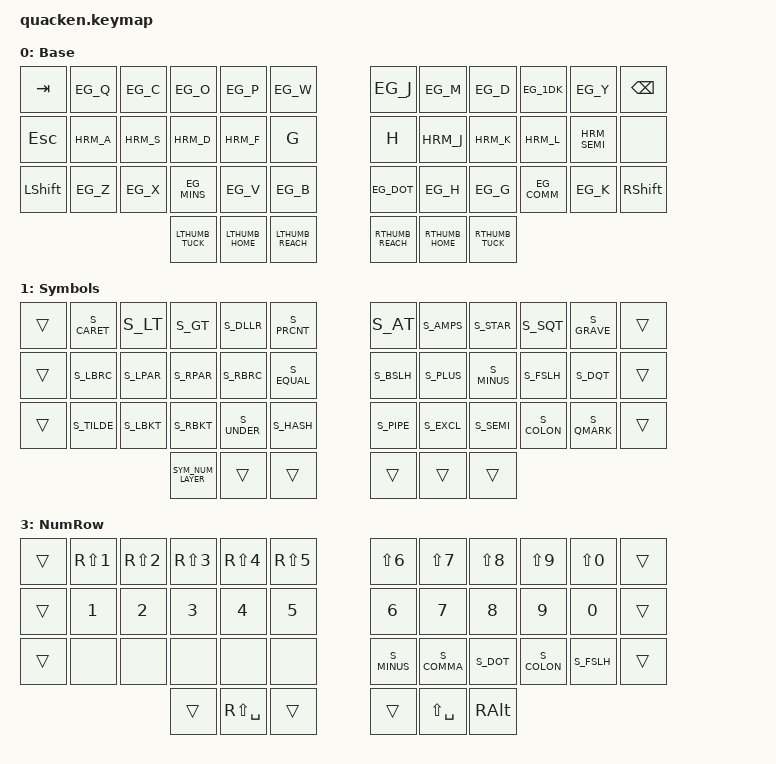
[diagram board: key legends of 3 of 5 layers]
// Selenium keymap:
// https://github.com/OneDeadKey/selenium

#ifndef CI_IGNORE_USER_SETTINGS
  #include "settings.h"   // user settings, ignored by CI tests
#endif

#include "aliases.h"      // symbols, actions, non-ASCII chars
#include "mappings.dtsi"  // key mapping helpers and macros
#include "my_hold_taps.dtsi" // thumb keys and homerow mods

/ {
  keymap {
    compatible = "zmk,keymap";

    // 0. Base layer -- keep the QWERTY key codes to use your OS keyboard layout
    //               -- the Space Cadet layer-tap on the right can be replaced by an AltGr/Enter mod-tap
    //               -- adjust the homerow mods with the #define statements above
    base_layer: base_layer {
      display-name = "Base";
      bindings = <
        &kp TAB    EG_Q    EG_C   EG_O    EG_P   EG_W         EG_J    EG_M    EG_D     EG_1DK   EG_Y       &kp BACKSPACE
        &kp ESCAPE HRM_A   HRM_S  HRM_D   HRM_F  &kp G        &kp H   HRM_J   HRM_K    HRM_L    HRM_SEMI   &none
        &kp LSHIFT EG_Z    EG_X   EG_MINS EG_V   EG_B         EG_DOT  EG_H    EG_G     EG_COMM  EG_K       &kp RSHIFT
                LTHUMB_TUCK  LTHUMB_HOME  LTHUMB_REACH    RTHUMB_REACH  RTHUMB_HOME  RTHUMB_TUCK
      >;
    };

    // 1. Symbols layer -- with Ergo-L, basically just an AltGr layer with custom thumb keys
    //                  -- can be redefined for non-AltGr layouts such as QWERTY-ANSI
    symbols_layer: symbols_layer {
      display-name = "Symbols";
      bindings = <
        &trans  S_CARET S_LT    S_GT    S_DLLR  S_PRCNT       S_AT    S_AMPS  S_STAR  S_SQT   S_GRAVE  &trans
        &trans  S_LBRC  S_LPAR  S_RPAR  S_RBRC  S_EQUAL       S_BSLH  S_PLUS  S_MINUS S_FSLH  S_DQT    &trans
        &trans  S_TILDE S_LBKT  S_RBKT  S_UNDER S_HASH        S_PIPE  S_EXCL  S_SEMI  S_COLON S_QMARK  &trans
                         SYM_NUM_LAYER  &trans  &trans        &trans  &trans  &trans
      >;
    };

    // 2. VimNav layer -- HJKL arrow cluster on the right hand
    //                 -- best used along with the NumRow layer
    //                 -- keyboard shortcuts on the left hand are adjusted to the OS layout (Ergo-L here)
    vim_nav_layer: vim_nav_layer {
      display-name = "VimNav";
      bindings = <
        &trans  &none    X_CTL_W  &vim_prev &vim_next &none        &none    &kp HOME  &kp PG_DN &kp PG_UP &kp END   &trans
        &trans  X_ALL    X_SAVE  X_SHTAB   H_F TAB   &none         &none    &kp LEFT  &kp DOWN  &kp UP    &kp RIGHT &trans
        &trans  X_UNDO   X_CUT    X_COPY    X_PASTE   X_REDO       &none    CLOSE_T   PREV_T    NEXT_T    OPEN_T    &trans
          &kp CAPS  &lt FN_MEDIA_LAYER DEL  &mo NUM_ROW_LAYER    &trans  &mo FN_MEDIA_LAYER  &EZ_LSK(RALT)
      >;
    };

    // 3. NumRow layer -- bring the numbers to the homerow, keep shift+numbers for shortcuts and symbols
    //                 -- space becomes shift+space, which is a no-break space with some OS layouts (e.g. Ergo-L)
    //                 -- best used along with the VimNav layer
    num_row_layer: num_row_layer {
      display-name = "NumRow";
      bindings = <
        &trans  &kp RS(N1) &kp RS(N2) &kp RS(N3) &kp RS(N4) &kp RS(N5)       &kp LS(N6) &kp LS(N7) &kp LS(N8) &kp LS(N9) &kp LS(N0) &trans
        &trans  &kp N1     &kp N2     &kp N3     &kp N4     &kp N5           &kp N6     &kp N7     &kp N8     &kp N9     &kp N0     &trans
        &trans  &none      &none      &none      &none      &none            S_MINUS    S_COMMA    S_DOT      S_COLON    S_FSLH     &trans
                                      &trans  &kp RS(SPACE) &trans           &trans  &kp LS(SPACE) &kp RALT
      >;
    };

    // 4. FnMedia layer -- F1..12 pad on the left hand, HRM on the right hand
    //                  -- reset and bootloader reset on difficult thumb keys
    //                  -- could be completed with other rare keys
    fn_media_layer: fn_media_layer {
      display-name = "FnMedia";
      bindings = <
        &trans  &kp F1  &kp F2  &kp F3  &kp F4  &none         &none  &kp C_PREV  &kp C_VOL_UP  &kp C_BRI_UP   &kp SLCK      &trans
        &trans  &kp F5  &kp F6  &kp F7  &kp F8  &none         &none  H_J C_PP    H_K C_MUTE    H_L C_AL_LOCK  H_SEMI PSCRN  &trans
        &trans  &kp F9  &kp F10 &kp F11 &kp F12 &none         &none  &kp C_NEXT  &kp C_VOL_DN  &kp C_BRI_DN   &kp INS       &trans
                                &trans  &trans  &bootloader   &sys_reset  &trans  &studio_unlock
      >;
    };
  };
};
